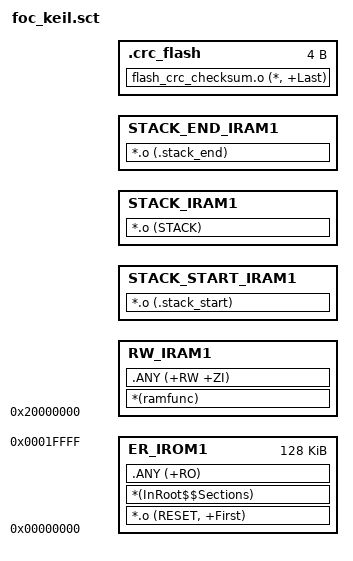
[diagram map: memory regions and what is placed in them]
; *************************************************************
; *** Scatter-Loading Description File generated by uVision ***
; *************************************************************

LR_IROM1 0x00000000 0x00020000  {    ; load region size_region
  ER_IROM1 0x00000000 0x00020000  {  ; load address = execution address
   *.o (RESET, +First)
   *(InRoot$$Sections)
   .ANY (+RO)
  }
  RW_IRAM1 0x20000000  {  ; RW data
   *(ramfunc)
   .ANY (+RW +ZI)
  }
  
  ;===== Stack Regions =====
  STACK_START_IRAM1 (ImageLimit(RW_IRAM1))  {  
    *.o (.stack_start)                            ; .stack_start section reserves 32-bits for stack checking mechanism
  }
  STACK_IRAM1 (ImageLimit(STACK_START_IRAM1))  {
    *.o (STACK)
  }
  STACK_END_IRAM1 (ImageLimit(STACK_IRAM1))  {  
    *.o (.stack_end)                            ; .stack_end section reserves 32-bits for stack checking mechanism
  }
}

LR_IROM1_END +0 0x4
{
  .crc_flash +0 0x4
  {
    flash_crc_checksum.o (*, +Last)
  }
}

ScatterAssert((ImageLength(RW_IRAM1) + ImageLength(STACK_IRAM1) + ImageLength(STACK_END_IRAM1)) < 0x8000) ; Check used ram
